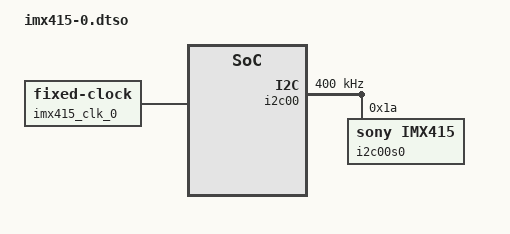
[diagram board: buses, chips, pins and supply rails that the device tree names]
// SPDX-License-Identifier: (GPL-2.0+ OR MIT)
/*
 * Copyright (c) 2025 SiMa ai
 */

/dts-v1/;
/plugin/;

/ {
    fragment@10 {
        target-path = "/"; /* Root node of the base tree */
        __overlay__ {
            imx415_clk_0: csi0_camera-clk {
                compatible = "fixed-clock";
                #clock-cells = <0>;
                clock-frequency = <37125000>;
            };
        };
    };
};

&i2c00 {
	status = "okay";
	clock-frequency = <400000>;
	#address-cells = <1>;
	#size-cells = <0>;

	i2c00s0: sensor@1a {
		compatible = "sony,imx415";
		reg = <0x1a>;
		clocks = <&imx415_clk_0>;
		clock-names = "inck";
	};
};
